VERSION ""

NS_ :

BS_:

BU_: vcu

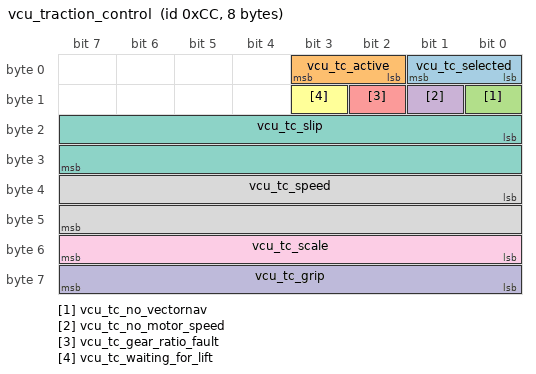
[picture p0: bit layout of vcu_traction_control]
BO_ 204 vcu_traction_control: 8 vcu
 SG_ vcu_tc_selected : 0|2@1+ (1,0) [0|2] "" Vector__XXX
 SG_ vcu_tc_active : 2|2@1+ (1,0) [0|2] "" Vector__XXX
 SG_ vcu_tc_no_vectornav : 8|1@1+ (1,0) [0|1] "bool" Vector__XXX
 SG_ vcu_tc_no_motor_speed : 9|1@1+ (1,0) [0|1] "bool" Vector__XXX
 SG_ vcu_tc_gear_ratio_fault : 10|1@1+ (1,0) [0|1] "bool" Vector__XXX
 SG_ vcu_tc_waiting_for_lift : 11|1@1+ (1,0) [0|1] "bool" Vector__XXX
 SG_ vcu_tc_slip : 16|16@1- (0.001,0) [-32.768|32.767] "" Vector__XXX
 SG_ vcu_tc_speed : 32|16@1+ (0.01,0) [0|655.35] "m/s" Vector__XXX
 SG_ vcu_tc_scale : 48|8@1+ (0.01,0) [0|2.55] "" Vector__XXX
 SG_ vcu_tc_grip : 56|8@1+ (0.02,0) [0|5.1] "" Vector__XXX

CM_ BO_ 204 "Traction control status, 20 Hz on the DAQ bus. Not in ksu-ms-dbc yet: kms-vcu docs/traction-control.md";
CM_ SG_ 204 vcu_tc_selected "What the driver or pits chose";
CM_ SG_ 204 vcu_tc_active "What's controlling now: 0 while it has stepped aside";
CM_ SG_ 204 vcu_tc_slip "Rear slip ratio the controller measures";
CM_ SG_ 204 vcu_tc_speed "Ground speed estimate";
CM_ SG_ 204 vcu_tc_scale "Torque multiplier (grip map: may exceed 1 over the map)";
CM_ SG_ 204 vcu_tc_grip "Grip map mode: learned friction coefficient";
VAL_ 204 vcu_tc_selected 0 "off" 1 "slip" 2 "grip map" ;
VAL_ 204 vcu_tc_active 0 "off" 1 "slip" 2 "grip map" ;
